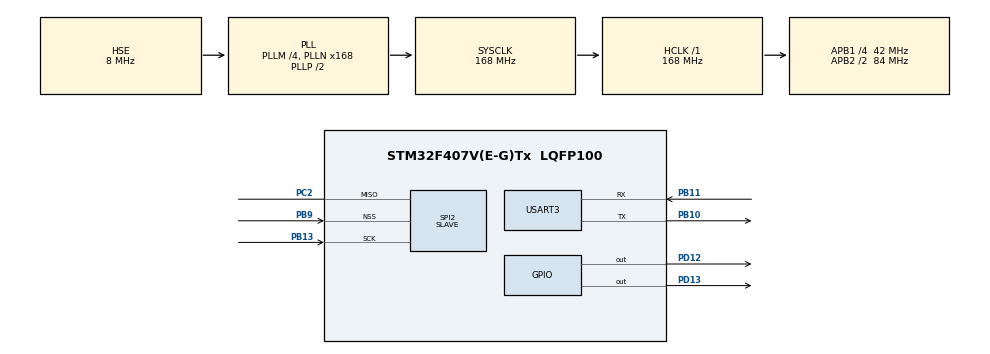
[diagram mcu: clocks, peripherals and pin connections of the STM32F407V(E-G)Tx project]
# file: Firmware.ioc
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Mcu.Family=STM32F4
Mcu.Name=STM32F407V(E-G)Tx
Mcu.Package=LQFP100
NVIC.PriorityGroup=NVIC_PRIORITYGROUP_4
NVIC.SPI2_IRQn=true\:0\:0\:false\:true\:true\:2\:true\:true
NVIC.USART3_IRQn=true\:0\:0\:false\:true\:true\:3\:true\:true
PB10.Mode=Asynchronous
PB10.Signal=USART3_TX
PB11.Mode=Asynchronous
PB11.Signal=USART3_RX
PB13.Mode=Simplex_Bidirectional_Slave
PB13.Signal=SPI2_SCK
PB9.Mode=NSS_Signal_Hard_Input
PB9.Signal=SPI2_NSS
PC2.Mode=Simplex_Bidirectional_Slave
PC2.Signal=SPI2_MISO
PD12.Signal=GPIO_Output
PD13.Signal=GPIO_Output
PH0-OSC_IN.Mode=HSE-External-Oscillator
PH0-OSC_IN.Signal=RCC_OSC_IN
PH1-OSC_OUT.Mode=HSE-External-Oscillator
PH1-OSC_OUT.Signal=RCC_OSC_OUT
ProjectManager.HeapSize=0x200
ProjectManager.StackSize=0x400
ProjectManager.TargetToolchain=SW4STM32
RCC.48MHZClocksFreq_Value=84000000
RCC.AHBFreq_Value=168000000
RCC.APB1CLKDivider=RCC_HCLK_DIV4
RCC.APB1Freq_Value=42000000
RCC.APB1TimFreq_Value=84000000
RCC.APB2CLKDivider=RCC_HCLK_DIV2
RCC.APB2Freq_Value=84000000
RCC.APB2TimFreq_Value=168000000
RCC.CortexFreq_Value=168000000
RCC.HCLKFreq_Value=168000000
RCC.HSE_VALUE=8000000
RCC.HSI_VALUE=16000000
RCC.LSE_VALUE=32768
RCC.PLLM=4
RCC.PLLN=168
RCC.PLLSourceVirtual=RCC_PLLSOURCE_HSE
RCC.SYSCLKFreq_VALUE=168000000
RCC.SYSCLKSource=RCC_SYSCLKSOURCE_PLLCLK
RCC.VCOOutputFreq_Value=336000000
SPI2.Direction=SPI_DIRECTION_1LINE
SPI2.Mode=SPI_MODE_SLAVE
SPI2.VirtualNSS=VM_NSSHARD
SPI2.VirtualType=VM_SLAVE
USART3.VirtualMode=VM_ASYNC
board=custom

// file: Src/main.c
/* USER CODE BEGIN Header */
/**
  ******************************************************************************
  * @file           : main.c
  * @brief          : Main program body
  ******************************************************************************
  * @attention
  *
  * <h2><center>&copy; Copyright (c) 2019 STMicroelectronics.
  * All rights reserved.</center></h2>
  *
  * This software component is licensed by ST under BSD 3-Clause license,
  * the "License"; You may not use this file except in compliance with the
  * License. You may obtain a copy of the License at:
  *                        opensource.org/licenses/BSD-3-Clause
  *
  ******************************************************************************
  */
/* USER CODE END Header */

#include "main.h"

SPI_HandleTypeDef hspi2;

UART_HandleTypeDef huart3;

/* USER CODE BEGIN PV */
unsigned char temp_main[20];
/* USER CODE END PV */

void SystemClock_Config(void);
static void MX_GPIO_Init(void);
static void MX_SPI2_Init(void);
static void MX_USART3_UART_Init(void);
static void MX_NVIC_Init(void);

/* USER CODE BEGIN 0 */
uint8_t RxBuffer[10];
uint8_t TxBuffer[10];
HAL_StatusTypeDef SPIStatus;
/* USER CODE END 0 */

int main(void)
{

  /* MCU Configuration--------------------------------------------------------*/

  /* Reset of all peripherals, Initializes the Flash interface and the Systick. */
  HAL_Init();

  /* USER CODE BEGIN Init */
  MX_GPIO_Init();
  MX_SPI2_Init();
  MX_USART3_UART_Init();
 // BufferInit();
  WIFIModuleInit();
  WIFIModuleSetWIFIName("Amin");
  WIFIModuleSetWIFIPassword("PASSWORD");
  //SetWIFISSID("NAME");
  //SetWIFIPassword("PASSWORD");
  /* USER CODE END Init */

  /* Initialize all configured peripherals */

  /* Initialize interrupts */
  MX_NVIC_Init();
  /* USER CODE BEGIN 2 */
__HAL_SPI_ENABLE_IT(&hspi2,SPI_IT_RXNE);
__HAL_SPI_ENABLE(&hspi2);
  /* USER CODE END 2 */

  /* Infinite loop */
  /* USER CODE BEGIN WHILE */
  while (1)
  {
	  GPIOD->ODR^=1<<13;

	  //sprintf(temp_main,"Status=%d\n",SPIStatus);
	  //HAL_UART_Transmit(&huart3, temp_main, sizeof(temp_main), HAL_MAX_DELAY);
	  HAL_Delay(300);
    /* USER CODE END WHILE */

  }
}

void SystemClock_Config(void)
{
  RCC_OscInitTypeDef RCC_OscInitStruct = {0};
  RCC_ClkInitTypeDef RCC_ClkInitStruct = {0};

  /** Configure the main internal regulator output voltage
  */
  __HAL_RCC_PWR_CLK_ENABLE();
  __HAL_PWR_VOLTAGESCALING_CONFIG(PWR_REGULATOR_VOLTAGE_SCALE1);
  /** Initializes the CPU, AHB and APB busses clocks
  */
  RCC_OscInitStruct.OscillatorType = RCC_OSCILLATORTYPE_HSE;
  RCC_OscInitStruct.HSEState = RCC_HSE_ON;
  RCC_OscInitStruct.PLL.PLLState = RCC_PLL_ON;
  RCC_OscInitStruct.PLL.PLLSource = RCC_PLLSOURCE_HSE;
  RCC_OscInitStruct.PLL.PLLM = 4;
  RCC_OscInitStruct.PLL.PLLN = 168;
  RCC_OscInitStruct.PLL.PLLP = RCC_PLLP_DIV2;
  RCC_OscInitStruct.PLL.PLLQ = 4;
  if (HAL_RCC_OscConfig(&RCC_OscInitStruct) != HAL_OK)
  {
    Error_Handler();
  }
  /** Initializes the CPU, AHB and APB busses clocks
  */
  RCC_ClkInitStruct.ClockType = RCC_CLOCKTYPE_HCLK|RCC_CLOCKTYPE_SYSCLK
                              |RCC_CLOCKTYPE_PCLK1|RCC_CLOCKTYPE_PCLK2;
  RCC_ClkInitStruct.SYSCLKSource = RCC_SYSCLKSOURCE_PLLCLK;
  RCC_ClkInitStruct.AHBCLKDivider = RCC_SYSCLK_DIV1;
  RCC_ClkInitStruct.APB1CLKDivider = RCC_HCLK_DIV4;
  RCC_ClkInitStruct.APB2CLKDivider = RCC_HCLK_DIV2;

  if (HAL_RCC_ClockConfig(&RCC_ClkInitStruct, FLASH_LATENCY_5) != HAL_OK)
  {
    Error_Handler();
  }
}

/**
  * @brief NVIC Configuration.
  * @retval None
  */
static void MX_NVIC_Init(void)
{
  /* SPI2_IRQn interrupt configuration */
  HAL_NVIC_SetPriority(SPI2_IRQn, 0, 0);
  HAL_NVIC_EnableIRQ(SPI2_IRQn);
  /* USART3_IRQn interrupt configuration */
  HAL_NVIC_SetPriority(USART3_IRQn, 0, 0);
  HAL_NVIC_EnableIRQ(USART3_IRQn);
}

static void MX_SPI2_Init(void)
{

  /* SPI2 parameter configuration*/
  hspi2.Instance = SPI2;
  hspi2.Init.Mode = SPI_MODE_SLAVE;
  hspi2.Init.Direction = SPI_DIRECTION_2LINES;
  hspi2.Init.DataSize = SPI_DATASIZE_8BIT;
  hspi2.Init.CLKPolarity = SPI_POLARITY_LOW;
  hspi2.Init.CLKPhase = SPI_PHASE_1EDGE;
  hspi2.Init.NSS = SPI_NSS_HARD_INPUT;
  hspi2.Init.FirstBit = SPI_FIRSTBIT_MSB;
  hspi2.Init.TIMode = SPI_TIMODE_DISABLE;
  hspi2.Init.CRCCalculation = SPI_CRCCALCULATION_DISABLE;
  hspi2.Init.CRCPolynomial = 10;
  if (HAL_SPI_Init(&hspi2) != HAL_OK)
  {
    Error_Handler();
  }

}

static void MX_USART3_UART_Init(void)
{

  huart3.Instance = USART3;
  huart3.Init.BaudRate = 115200;
  huart3.Init.WordLength = UART_WORDLENGTH_8B;
  huart3.Init.StopBits = UART_STOPBITS_1;
  huart3.Init.Parity = UART_PARITY_NONE;
  huart3.Init.Mode = UART_MODE_TX_RX;
  huart3.Init.HwFlowCtl = UART_HWCONTROL_NONE;
  huart3.Init.OverSampling = UART_OVERSAMPLING_16;
  if (HAL_UART_Init(&huart3) != HAL_OK)
  {
    Error_Handler();
  }

}

static void MX_GPIO_Init(void)
{
  GPIO_InitTypeDef GPIO_InitStruct = {0};

  /* GPIO Ports Clock Enable */
  __HAL_RCC_GPIOH_CLK_ENABLE();
  __HAL_RCC_GPIOC_CLK_ENABLE();
  __HAL_RCC_GPIOB_CLK_ENABLE();
  __HAL_RCC_GPIOD_CLK_ENABLE();

  /*Configure GPIO pin Output Level */
  HAL_GPIO_WritePin(GPIOD, GPIO_PIN_12|GPIO_PIN_13, GPIO_PIN_RESET);

  /*Configure GPIO pins : PD12 PD13 */
  GPIO_InitStruct.Pin = GPIO_PIN_12|GPIO_PIN_13;
  GPIO_InitStruct.Mode = GPIO_MODE_OUTPUT_PP;
  GPIO_InitStruct.Pull = GPIO_NOPULL;
  GPIO_InitStruct.Speed = GPIO_SPEED_FREQ_LOW;
  HAL_GPIO_Init(GPIOD, &GPIO_InitStruct);

}

void Error_Handler(void)
{
}

/************************ (C) COPYRIGHT STMicroelectronics *****END OF FILE****/
